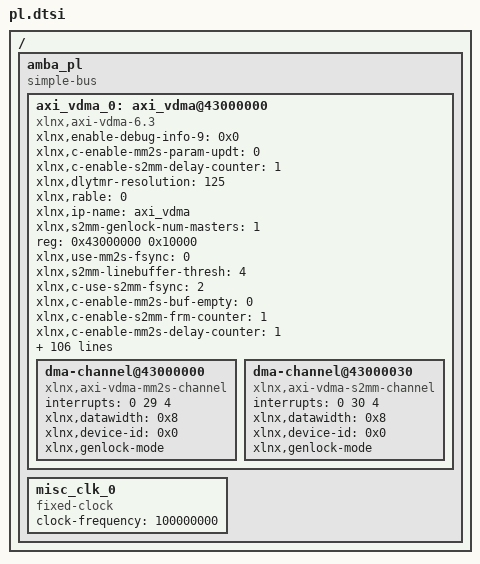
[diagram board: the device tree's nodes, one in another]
/ {
	amba_pl: amba_pl {
		ranges;
		compatible = "simple-bus";
		#address-cells = <1>;
		#size-cells = <1>;
		axi_vdma_0: axi_vdma@43000000 {
			xlnx,enable-debug-info-9 = <0x0>;
			xlnx,c-enable-mm2s-param-updt = <0>;
			xlnx,c-enable-s2mm-delay-counter = <1>;
			xlnx,dlytmr-resolution = <125>;
			xlnx,rable = <0>;
			xlnx,ip-name = "axi_vdma";
			xlnx,s2mm-genlock-num-masters = <1>;
			reg = <0x43000000 0x10000>;
			xlnx,use-mm2s-fsync = <0>;
			xlnx,s2mm-linebuffer-thresh = <4>;
			xlnx,c-use-s2mm-fsync = <2>;
			xlnx,c-enable-mm2s-buf-empty = <0>;
			xlnx,c-enable-s2mm-frm-counter = <1>;
			xlnx,c-enable-mm2s-delay-counter = <1>;
			xlnx,c-dlytmr-resolution = <125>;
			xlnx,c-enable-s2mm-buf-full = <0>;
			xlnx,dynamic-resolution = <1>;
			interrupt-names = "mm2s_introut" , "s2mm_introut";
			xlnx,s2mm-sof-enable = <0x1>;
			xlnx,mm2s-genlock-num-masters = <1>;
			xlnx,c-s2mm-genlock-num-masters = <1>;
			xlnx,c-enable-s2mm-fsync-out = <0>;
			xlnx,mm2s-linebuffer-thresh = <4>;
			xlnx,c-use-mm2s-fsync = <0>;
			xlnx,c-s2mm-linebuffer-thresh = <4>;
			xlnx,c-enable-mm2s-frm-counter = <1>;
			compatible = "xlnx,axi-vdma-6.3" , "xlnx,axi-vdma-1.00.a";
			xlnx,c-m-axis-mm2s-tdata-width = <8>;
			xlnx,c-enable-all = <0>;
			interrupt-parent = <&intc>;
			xlnx,s2mm-max-burst-length = <8>;
			xlnx,c-dynamic-resolution = <1>;
			xlnx,c-enable-s2mm-rst-out = <0>;
			xlnx,mm2s-sof-enable = <1>;
			xlnx,include-s2mm-dre = <0x0>;
			xlnx,c-s2mm-sof-enable = <1>;
			xlnx,c-enable-mm2s-fsync-out = <0>;
			xlnx,c-mm2s-genlock-num-masters = <1>;
			xlnx,c-mm2s-linebuffer-thresh = <4>;
			xlnx,c-enable-tstvec = <0>;
			xlnx,mm2s-max-burst-length = <16>;
			xlnx,c-s2mm-max-burst-length = <8>;
			status = "okay";
			xlnx,c-enable-mm2s-rst-out = <0>;
			xlnx,include-mm2s-dre = <0x0>;
			xlnx,c-include-s2mm-dre = <0>;
			xlnx,c-mm2s-sof-enable = <1>;
			xlnx,name = "axi_vdma_0";
			xlnx,c-enable-s2mm-frmstr-reg = <0>;
			interrupts = < 0 29 4 0 30 4 >;
			xlnx,c-include-sg = <0>;
			xlnx,flush-on-fsync = <0x1>;
			xlnx,c-m-axi-s2mm-data-width = <32>;
			xlnx,c-enable-s2mm-sts-reg = <0>;
			xlnx,include-s2mm-sf = <1>;
			xlnx,c-mm2s-max-burst-length = <16>;
			xlnx,s2mm-linebuffer-depth = <0x200>;
			xlnx,include-s2mm = <0x1>;
			xlnx,c-include-mm2s-dre = <0>;
			clocks = <&misc_clk_0>, <&misc_clk_0>, <&misc_clk_0>, <&misc_clk_0>, <&misc_clk_0>;
			xlnx,c-enable-mm2s-frmstr-reg = <0>;
			xlnx,enable-debug-info-10 = <0>;
			xlnx,addrwidth = <0x20>;
			xlnx,enable-debug-info-11 = <0>;
			xlnx,enable-debug-info-12 = <0>;
			xlnx,edk-iptype = "PERIPHERAL";
			xlnx,c-flush-on-fsync = <1>;
			xlnx,c-m-axi-mm2s-data-width = <32>;
			xlnx,use-fsync = <1>;
			xlnx,s2mm-genlock-repeat-en = <1>;
			xlnx,enable-vert-flip = <0x0>;
			xlnx,enable-debug-info-13 = <0x0>;
			xlnx,include-mm2s-sf = <0>;
			xlnx,include-internal-genlock = <0x1>;
			xlnx,enable-debug-info-14 = <0x1>;
			xlnx,c-include-s2mm-sf = <1>;
			clock-names = "s_axi_lite_aclk" , "m_axi_mm2s_aclk" , "m_axis_mm2s_aclk" , "m_axi_s2mm_aclk" , "s_axis_s2mm_aclk";
			xlnx,enable-debug-info-15 = <0x1>;
			xlnx,mm2s-linebuffer-depth = <0x200>;
			xlnx,include-mm2s = <0x1>;
			xlnx,c-single-interface = <0>;
			xlnx,c-s2mm-linebuffer-depth = <512>;
			xlnx,c-addr-width = <32>;
			xlnx,c-include-s2mm = <1>;
			xlnx,s2mm-genlock-mode = <0x2>;
			xlnx,c-s-axis-s2mm-tdata-width = <8>;
			xlnx,flush-fsync = <0x1>;
			xlnx,select-xpm = <0>;
			xlnx,s2mm-data-width = <0x20>;
			xlnx,num-fstores = <0x3>;
			xlnx,enable-vidparam-reads = <0x1>;
			xlnx,mm2s-genlock-repeat-en = <0>;
			xlnx,c-use-fsync = <1>;
			xlnx,c-s2mm-genlock-repeat-en = <1>;
			xlnx,c-enable-vert-flip = <0>;
			xlnx,prmry-is-aclk-async = <0>;
			xlnx,c-include-internal-genlock = <1>;
			xlnx,c-include-mm2s-sf = <0>;
			xlnx,s2mm-tdata-width = <0x8>;
			xlnx,enable-vidprmtr-reads = <1>;
			xlnx,c-include-mm2s = <1>;
			xlnx,c-mm2s-linebuffer-depth = <512>;
			xlnx,mm2s-genlock-mode = <0x3>;
			xlnx,enable-debug-info-0 = <0>;
			xlnx,enable-debug-all = <0x0>;
			xlnx,c-s2mm-genlock-mode = <2>;
			xlnx,enable-debug-info-1 = <0x0>;
			xlnx,mm2s-data-width = <0x20>;
			xlnx,enable-debug-info-2 = <0>;
			xlnx,c-enable-s2mm-param-updt = <0>;
			xlnx,c-num-fstores = <3>;
			xlnx,enable-debug-info-3 = <0>;
			xlnx,enable-debug-info-4 = <0>;
			xlnx,c-mm2s-genlock-repeat-en = <0>;
			xlnx,enable-debug-info-5 = <0x0>;
			xlnx,c-prmry-is-aclk-async = <0>;
			xlnx,mm2s-tdata-width = <0x8>;
			xlnx,enable-debug-info-6 = <0x1>;
			xlnx,enable-debug-info-7 = <0x1>;
			xlnx,c-enable-vidprmtr-reads = <1>;
			xlnx,use-s2mm-fsync = <2>;
			xlnx,enable-debug-info-8 = <0>;
			xlnx,c-mm2s-genlock-mode = <3>;
			dma-channel@43000000 {
				interrupts = < 0 29 4 >;
				xlnx,datawidth = <0x8>;
				xlnx,device-id = <0x0>;
				compatible = "xlnx,axi-vdma-mm2s-channel";
				xlnx,genlock-mode;
			};
			dma-channel@43000030 {
				interrupts = < 0 30 4 >;
				xlnx,datawidth = <0x8>;
				xlnx,device-id = <0x0>;
				compatible = "xlnx,axi-vdma-s2mm-channel";
				xlnx,genlock-mode;
			};
		};
		misc_clk_0: misc_clk_0 {
			compatible = "fixed-clock";
			clock-frequency = <100000000>;
			#clock-cells = <0>;
		};
	};
};
